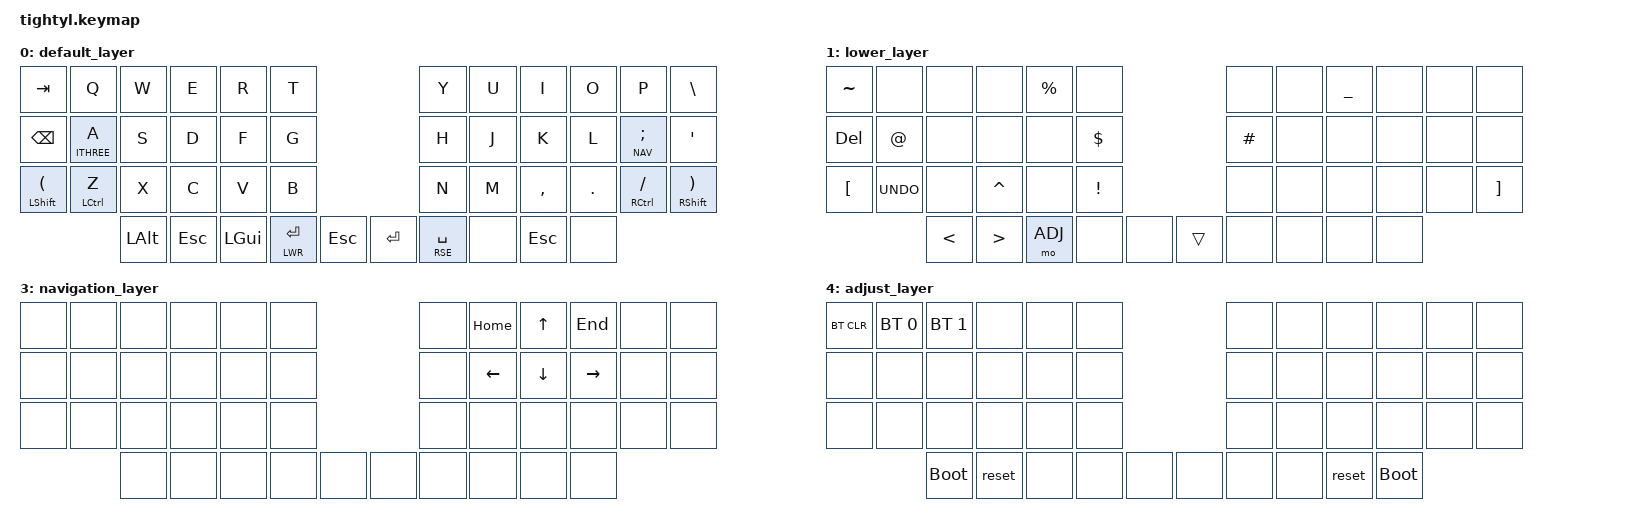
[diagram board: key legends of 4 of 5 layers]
#include <behaviors.dtsi>
#include <dt-bindings/zmk/keys.h>
#include <dt-bindings/zmk/bt.h>

#define DEF 0
#define LWR 1
#define RSE 2
#define NAV 3
#define ADJ 4
#define ITHREE  5

/ {
        keymap {
                compatible = "zmk,keymap";

                default_layer {
                        bindings = <
		&kp TAB   	   &kp Q       &kp W    &kp E   &kp R    &kp T         		   		 &kp Y    	   &kp U    &kp I     &kp O    &kp P          &kp BSLH
 		&kp BSPC  	   &lt ITHREE A	   &kp S    &kp D   &kp F    &kp G             	         &kp H         &kp J    &kp K     &kp L    &lt NAV SEMI   &kp SQT
		&mt LSHFT LPAR &mt LCTRL Z &kp X    &kp C   &kp V    &kp B                       &kp N         &kp M    &kp COMMA &kp DOT  &mt RCTRL FSLH &mt RSHFT RPAR
	               			  	   &kp LALT &kp ESC &kp LGUI &lt LWR RET &kp ESC &kp RET &lt RSE SPACE &none 	&kp ESC   &none 
                        >;
                };
                lower_layer {bindings = <
		&kp TILDE &none      &none  &none     &kp PRCNT &none                  &none    &none &kp UNDER &none &none &none
		&kp DEL   &kp AT     &none  &none     &none     &kp DLLR      		   &kp HASH &none &none     &none &none &none
		&kp LBKT  &kp K_UNDO &none  &kp CARET &none     &kp EXCL               &none    &none &none     &none &none &kp RBKT
							 &kp LT &kp GT    &mo ADJ   &none    &none &trans  &none    &none &none     &none
                        >;
                };
                raise_layer {bindings = <
		&none     &none    &none &none &none &none        	 &kp KP_MINUS &kp N7   &kp N8 &kp N9  &none     &none
		&kp BSPC  &kp AMPS &none &none &none &none      	 &kp ASTRK    &kp N4   &kp N5 &kp N6  &kp EQUAL &none
		&kp LBRC  &none    &none &none &none &none           &kp PLUS     &kp N1   &kp N2 &kp N3  &none     &kp RBRC
						   &none &none &none &none &none     &none        &mo ADJ  &kp N0 &kp DOT          
                        >;
                };
                navigation_layer {bindings = <
		&none &none &none &none &none &none        		&none &kp HOME &kp UP   &kp END   &none &none
		&none &none &none &none &none &none      		&none &kp LEFT &kp DOWN &kp RIGHT &none &none
		&none &none &none &none &none &none             &none &none    &none    &none     &none &none
					&none &none &none &none &none &none &none &none    &none    &none        
                        >;
                };
                adjust_layer {bindings = <
		&bt BT_CLR &bt BT_SEL 0 &bt BT_SEL 1 &none &none &none  &none &none &none &none &none &none
		&none &none &none &none &none &none      				&none &none &none &none &none &none
		&none &none &none &none &none &none             		&none &none &none &none &none &none
					&bootloader &reset &none &none &none &none &none &none &reset &bootloader     
                        >;
                
                };
                // i3_navigation_layer {bindings = <
		// &kp LGUI(SHFT(N1)) &kp LGUI(SHFT(N1)) &kp LGUI(SHFT(N2)) &LGUI(SHFT(N2))   &LGUI(SHFT(N2))  &LGUI(SHFT(N2))  &none &none &none &none    &none &none
		// &none &none &kp LGUI(R) &kp LGUI(DOWN) &kp LrUI(RIGHT) &none      		&none &none &none &none &none &none
		// &none &none &none &none &none &none             &none &none    &none    &none     &none &none
		// 			&none &none &none &none &none &none &none &none    &none    &none        
                //         >;
                // };
        };
};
